VERSION ""

NS_ :

BS_:

BU_: ECU_ENGINE ECU_BRAKE ECU_TRANSMISSION ECU_BODY ECU_DIAG TESTER

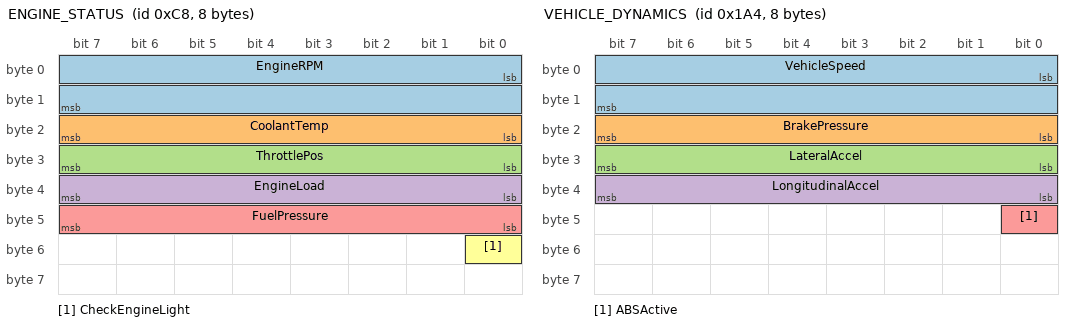
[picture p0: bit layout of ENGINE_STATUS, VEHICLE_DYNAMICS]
BO_ 200 ENGINE_STATUS: 8 ECU_ENGINE
 SG_ EngineRPM : 0|16@1+ (1.0,0.0) [0|6500] "rpm" ECU_TRANSMISSION,ECU_BODY
 SG_ CoolantTemp : 16|8@1+ (1.0,-40.0) [-40|215] "degC" ECU_BODY
 SG_ ThrottlePos : 24|8@1+ (1.0,0.0) [0|100] "%" ECU_TRANSMISSION
 SG_ EngineLoad : 32|8@1+ (0.392,0.0) [0|100] "%" ECU_BODY
 SG_ FuelPressure : 40|8@1+ (3.0,0.0) [0|765] "kPa" ECU_BODY
 SG_ CheckEngineLight : 48|1@1+ (1.0,0.0) [0|1] "" ECU_BODY

BO_ 420 VEHICLE_DYNAMICS: 8 ECU_BRAKE
 SG_ VehicleSpeed : 0|16@1+ (0.005,0.0) [0|327.67] "km/h" ECU_ENGINE,ECU_BODY
 SG_ BrakePressure : 16|8@1+ (0.1,0.0) [0|25.5] "MPa" ECU_BODY
 SG_ LateralAccel : 24|8@1- (0.1,0.0) [-12.7|12.7] "m/s2" ECU_BODY
 SG_ LongitudinalAccel : 32|8@1- (0.1,0.0) [-12.7|12.7] "m/s2" ECU_BODY
 SG_ ABSActive : 40|1@1+ (1.0,0.0) [0|1] "" ECU_ENGINE

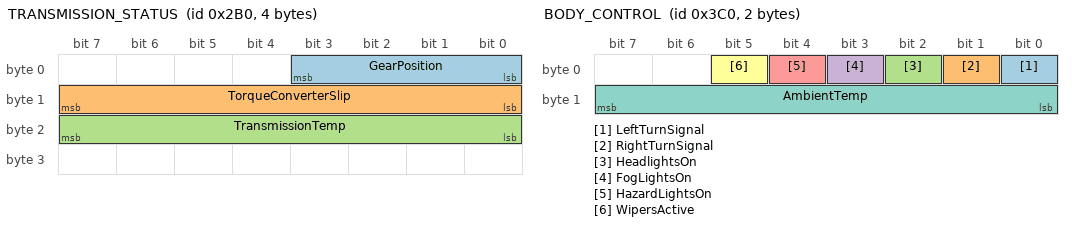
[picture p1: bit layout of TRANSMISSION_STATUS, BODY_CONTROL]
BO_ 688 TRANSMISSION_STATUS: 4 ECU_TRANSMISSION
 SG_ GearPosition : 0|4@1+ (1.0,0.0) [0|8] "" ECU_ENGINE,ECU_BODY
 SG_ TorqueConverterSlip : 8|8@1+ (1.0,0.0) [0|100] "%" ECU_ENGINE
 SG_ TransmissionTemp : 16|8@1+ (1.0,-40.0) [-40|215] "degC" ECU_BODY

BO_ 960 BODY_CONTROL: 2 ECU_BODY
 SG_ LeftTurnSignal : 0|1@1+ (1.0,0.0) [0|1] "" Vector__XXX
 SG_ RightTurnSignal : 1|1@1+ (1.0,0.0) [0|1] "" Vector__XXX
 SG_ HeadlightsOn : 2|1@1+ (1.0,0.0) [0|1] "" Vector__XXX
 SG_ FogLightsOn : 3|1@1+ (1.0,0.0) [0|1] "" Vector__XXX
 SG_ HazardLightsOn : 4|1@1+ (1.0,0.0) [0|1] "" Vector__XXX
 SG_ WipersActive : 5|1@1+ (1.0,0.0) [0|1] "" Vector__XXX
 SG_ AmbientTemp : 8|8@1- (0.5,-40.0) [-40|87.5] "degC" Vector__XXX

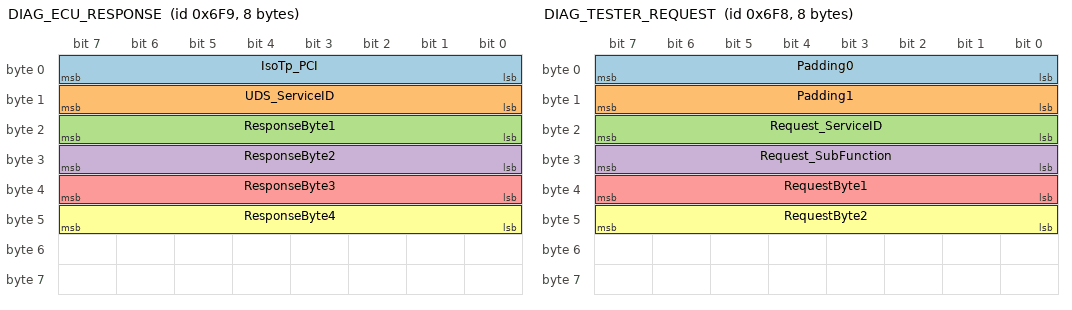
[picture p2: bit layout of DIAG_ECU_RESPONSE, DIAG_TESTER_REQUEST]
BO_ 1785 DIAG_ECU_RESPONSE: 8 ECU_DIAG
 SG_ IsoTp_PCI : 0|8@1+ (1.0,0.0) [0|255] "" TESTER
 SG_ UDS_ServiceID : 8|8@1+ (1.0,0.0) [0|255] "" TESTER
 SG_ ResponseByte1 : 16|8@1+ (1.0,0.0) [0|255] "" TESTER
 SG_ ResponseByte2 : 24|8@1+ (1.0,0.0) [0|255] "" TESTER
 SG_ ResponseByte3 : 32|8@1+ (1.0,0.0) [0|255] "" TESTER
 SG_ ResponseByte4 : 40|8@1+ (1.0,0.0) [0|255] "" TESTER

BO_ 1784 DIAG_TESTER_REQUEST: 8 TESTER
 SG_ Padding0 : 0|8@1+ (1.0,0.0) [0|255] "" ECU_DIAG
 SG_ Padding1 : 8|8@1+ (1.0,0.0) [0|255] "" ECU_DIAG
 SG_ Request_ServiceID : 16|8@1+ (1.0,0.0) [0|255] "" ECU_DIAG
 SG_ Request_SubFunction : 24|8@1+ (1.0,0.0) [0|255] "" ECU_DIAG
 SG_ RequestByte1 : 32|8@1+ (1.0,0.0) [0|255] "" ECU_DIAG
 SG_ RequestByte2 : 40|8@1+ (1.0,0.0) [0|255] "" ECU_DIAG

 0 "Park" 1 "Reverse" 2 "Neutral" 3 "Drive"
 4 "First" 5 "Second" 6 "Third" 7 "Fourth" 8 "Fifth" ;

 0 "SingleFrame_0bytes" 1 "SingleFrame_1byte" 2 "SingleFrame_2bytes"
 3 "SingleFrame_3bytes" 4 "SingleFrame_4bytes" 5 "SingleFrame_5bytes"
 6 "SingleFrame_6bytes" 7 "SingleFrame_7bytes"
 16 "FirstFrame" 32 "ConsecutiveFrame" 48 "FlowControl" ;

 16 "DiagnosticSessionControl"
 17 "ECUReset"
 34 "ReadDataByIdentifier"
 39 "SecurityAccess"
 46 "WriteDataByIdentifier"
 62 "TesterPresent"
 127 "NegativeResponse"
 12 "Proprietary_0x0C" ;

 16 "DiagnosticSessionControl"
 17 "ECUReset"
 34 "ReadDataByIdentifier"
 39 "SecurityAccess"
 46 "WriteDataByIdentifier"
 62 "TesterPresent"
 127 "NegativeResponse"
 12 "Proprietary_0x0C" ;

CM_ BO_ 1785 "UDS ECU response. ID=0x6F9.";
CM_ BO_ 1784 "UDS tester request. ID=0x6F8.";
CM_ SG_ 1785 IsoTp_PCI "ISO-TP Protocol Control Information.";
CM_ SG_ 1785 UDS_ServiceID "UDS service identifier.";
CM_ SG_ 200 EngineRPM "Engine speed in RPM. Redline at 6500.";
CM_ SG_ 200 CoolantTemp "Engine coolant temp. Normal range 85-105 degC.";
CM_ SG_ 420 VehicleSpeed "Wheel-speed-derived vehicle speed.";
CM_ SG_ 420 ABSActive "1 when ABS is actively pulsing brake pressure.";
CM_ SG_ 688 GearPosition "Current gear. See VAL_ table for enum mapping.";
